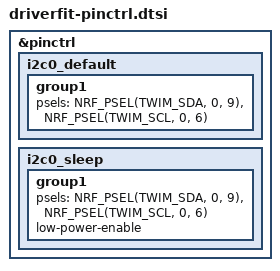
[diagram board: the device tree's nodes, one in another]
// Based on:
// https://github.com/zephyrproject-rtos/zephyr/blob/main/boards/arm/adafruit_feather_nrf52840/adafruit_feather_nrf52840-pinctrl.dtsi
// and https://developer.nordicsemi.com/nRF_Connect_SDK/doc/2.3.0/nrf/app_dev/pin_control/index.html

&pinctrl{
    i2c0_default: i2c0_default {
		group1 {
			psels = <NRF_PSEL(TWIM_SDA, 0, 9)>,
				<NRF_PSEL(TWIM_SCL, 0, 6)>;
		};
	};

	i2c0_sleep: i2c0_sleep {
		group1 {
			psels = <NRF_PSEL(TWIM_SDA, 0, 9)>,
				<NRF_PSEL(TWIM_SCL, 0, 6)>;
			low-power-enable;
		};
	};

	/* spi0_default: spi0_default {
		group1 {
			psels = <NRF_PSEL(SPIM_MOSI, 0, 29)>;
		};
	};

	spi0_sleep: spi0_sleep {
		group1 {
			psels = <NRF_PSEL(SPIM_MOSI, 0, 29)>;
			low-power-enable;
		};
	}; */
};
